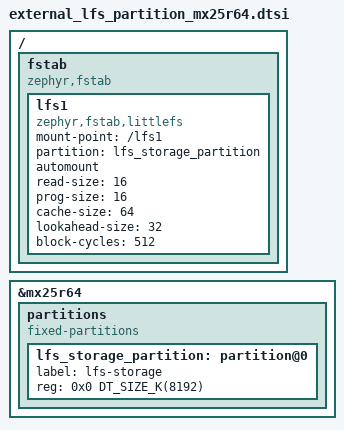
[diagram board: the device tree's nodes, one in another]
/*
 * Copyright (c) 2026 Nordic Semiconductor ASA
 *
 * SPDX-License-Identifier: LicenseRef-Nordic-5-Clause
 */

/*
 * Place the littlefs file system on the on-board MX25R64 external flash.
 */

&mx25r64 {
	status = "okay";

	partitions {
		compatible = "fixed-partitions";
		#address-cells = <1>;
		#size-cells = <1>;

		lfs_storage_partition: partition@0 {
			label = "lfs-storage";
			reg = <0x0 DT_SIZE_K(8192)>;
		};
	};
};

/ {
	/* Define the file system and mount it automatically at boot. */
	fstab {
		compatible = "zephyr,fstab";

		lfs1: lfs1 {
			compatible = "zephyr,fstab,littlefs";
			mount-point = "/lfs1";
			partition = <&lfs_storage_partition>;
			automount;
			read-size = <16>;
			prog-size = <16>;
			cache-size = <64>;
			lookahead-size = <32>;
			block-cycles = <512>;
		};
	};
};
